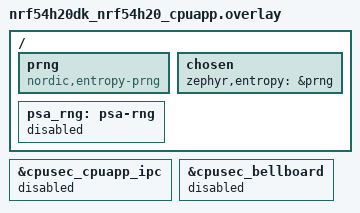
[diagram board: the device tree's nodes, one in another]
/* Copyright (c) 2024 Nordic Semiconductor ASA
 *
 * SPDX-License-Identifier: LicenseRef-Nordic-5-Clause
 */

/ {
	prng: prng {
		compatible = "nordic,entropy-prng";
		status = "okay";
	};

	chosen {
		zephyr,entropy = &prng;
	};

	psa_rng: psa-rng {
		status = "disabled";
	};
};


&cpusec_cpuapp_ipc {
	status = "disabled";
};

&cpusec_bellboard {
	status = "disabled";
};
